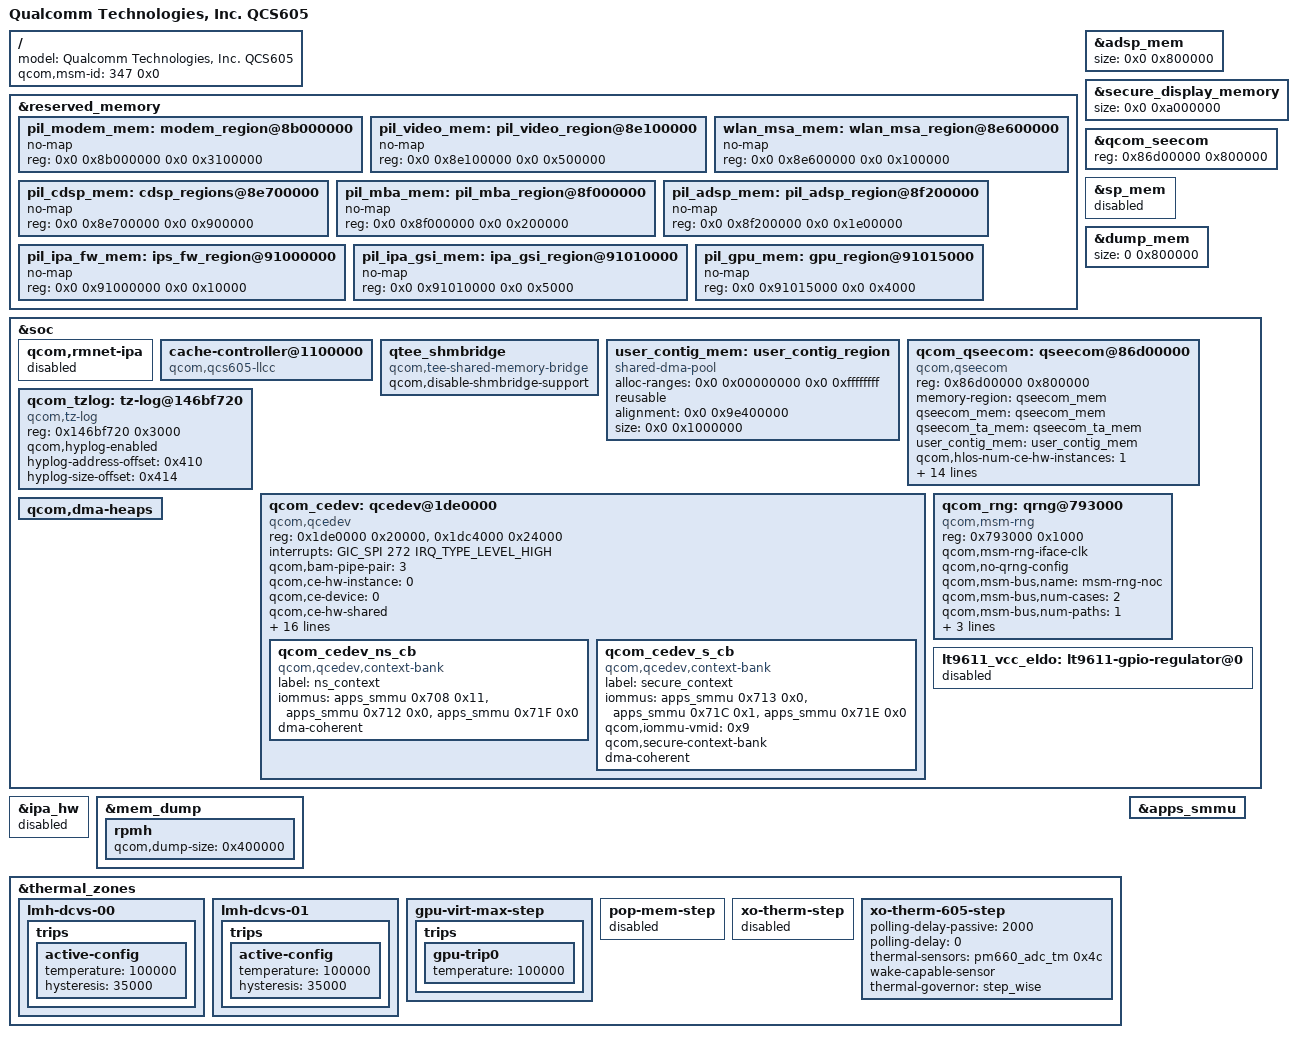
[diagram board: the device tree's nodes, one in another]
#include "sda670.dtsi"

/ {
	model = "Qualcomm Technologies, Inc. QCS605";
	qcom,msm-id = <347 0x0>;
};

&reserved_memory {
	/delete-node/ modem_region@8b000000;
	/delete-node/ pil_video_region@92e00000;
	/delete-node/ wlan_msa_region@93300000;
	/delete-node/ cdsp_regions@93400000;
	/delete-node/ pil_mba_region@0x93c00000;
	/delete-node/ pil_adsp_region@93e00000;
	/delete-node/ ips_fw_region@0x95c00000;
	/delete-node/ ipa_gsi_region@0x95c10000;
	/delete-node/ gpu_region@0x95c15000;

	pil_modem_mem: modem_region@8b000000 {
		no-map;
		reg = <0x0 0x8b000000 0x0 0x3100000>;
	};

	pil_video_mem: pil_video_region@8e100000 {
		no-map;
		reg = <0x0 0x8e100000 0x0 0x500000>;
	};

	wlan_msa_mem: wlan_msa_region@8e600000 {
		no-map;
		reg = <0x0 0x8e600000 0x0 0x100000>;
	};

	pil_cdsp_mem: cdsp_regions@8e700000 {
		no-map;
		reg = <0x0 0x8e700000 0x0 0x900000>;
	};

	pil_mba_mem: pil_mba_region@8f000000 {
		no-map;
		reg = <0x0 0x8f000000 0x0 0x200000>;
	};

	pil_adsp_mem: pil_adsp_region@8f200000 {
		no-map;
		reg = <0x0 0x8f200000 0x0 0x1e00000>;
	};

	pil_ipa_fw_mem: ips_fw_region@91000000 {
		no-map;
		reg = <0x0 0x91000000 0x0 0x10000>;
	};

	pil_ipa_gsi_mem: ipa_gsi_region@91010000 {
		no-map;
		reg = <0x0 0x91010000 0x0 0x5000>;
	};

	pil_gpu_mem: gpu_region@91015000 {
		no-map;
		reg = <0x0 0x91015000 0x0 0x4000>;
	};
};

&adsp_mem {
	size = <0x0 0x800000>;
};

&secure_display_memory {
	size = <0x0 0xa000000>;
};

&qcom_seecom {
	reg = <0x86d00000 0x800000>;
	/delete-property/ qcom,appsbl-qseecom-support;
};

&sp_mem {
	status = "disabled";
};

&dump_mem {
	size = <0 0x800000>;
};

&soc {
	qcom,rmnet-ipa {
		status = "disabled";
	};

	cache-controller@1100000 {
		/delete-property/ compatible;
		compatible = "qcom,qcs605-llcc";
	};

	qtee_shmbridge {
		compatible = "qcom,tee-shared-memory-bridge";
		qcom,disable-shmbridge-support;
	};

	user_contig_mem: user_contig_region {
		compatible = "shared-dma-pool";
		alloc-ranges = <0x0 0x00000000 0x0 0xffffffff>;
		reusable;
		alignment = <0x0 0x9e400000>;
		size = <0x0 0x1000000>;
	};

	qcom_qseecom: qseecom@86d00000 {
		compatible = "qcom,qseecom";
		reg = <0x86d00000 0x800000>;
		reg-names = "secapp-region";
		memory-region = <&qseecom_mem>;
		qseecom_mem = <&qseecom_mem>;
		qseecom_ta_mem = <&qseecom_ta_mem>;
		user_contig_mem = <&user_contig_mem>;
		qcom,hlos-num-ce-hw-instances = <1>;
		qcom,hlos-ce-hw-instance = <0>;
		qcom,qsee-ce-hw-instance = <0>;
		qcom,disk-encrypt-pipe-pair = <2>;
		qcom,no-clock-support;
		qcom,appsbl-qseecom-support;
		qcom,msm-bus,name = "qseecom-noc";
		qcom,msm-bus,num-cases = <4>;
		qcom,msm-bus,num-paths = <1>;
		qcom,msm-bus,vectors-KBps =
				<125 512 0 0>,
				<125 512 200000 400000>,
				<125 512 300000 800000>,
				<125 512 400000 1000000>;
		qcom,ce-opp-freq = <171430000>;
		qcom,qsee-reentrancy-support = <2>;
	};

	qcom_tzlog: tz-log@146bf720 {
		compatible = "qcom,tz-log";
		reg = <0x146bf720 0x3000>;
		qcom,hyplog-enabled;
		hyplog-address-offset = <0x410>;
		hyplog-size-offset = <0x414>;
	};

	qcom_cedev: qcedev@1de0000 {
	compatible = "qcom,qcedev";
	reg = <0x1de0000 0x20000>,
		<0x1dc4000 0x24000>;
	reg-names = "crypto-base","crypto-bam-base";
	interrupts = <GIC_SPI 272 IRQ_TYPE_LEVEL_HIGH>;
	qcom,bam-pipe-pair = <3>;
	qcom,ce-hw-instance = <0>;
	qcom,ce-device = <0>;
	qcom,ce-hw-shared;
	qcom,bam-ee = <0>;
	qcom,msm-bus,name = "qcedev-noc";
	qcom,msm-bus,num-cases = <2>;
	qcom,msm-bus,num-paths = <1>;
	qcom,msm-bus,vectors-KBps =
		<125 512 0 0>,
		<125 512 393600 393600>;
	clock-names = "core_clk_src", "core_clk",
		"iface_clk", "bus_clk";
	clocks = <&gcc GCC_CE1_CLK>,
		<&gcc GCC_CE1_CLK>,
		<&gcc GCC_CE1_AHB_CLK>,
		<&gcc GCC_CE1_AXI_CLK>;
	qcom,ce-opp-freq = <171430000>;
	qcom,request-bw-before-clk;
	qcom,smmu-s1-enable;
	interconnect-names = "data_path";
	interconnects = <&aggre2_noc MASTER_CRYPTO &mc_virt SLAVE_EBI1>;
	iommus = <&apps_smmu 0x706 0x1>,
		<&apps_smmu 0x716 0x1>;
	qcom,iommu-dma = "atomic";

	qcom_cedev_ns_cb {
		compatible = "qcom,qcedev,context-bank";
		label = "ns_context";
		iommus = <&apps_smmu 0x708 0x11>,
			<&apps_smmu 0x712 0x0>,
			<&apps_smmu 0x71F 0x0>;
		dma-coherent;
	};

	qcom_cedev_s_cb {
		compatible = "qcom,qcedev,context-bank";
		label = "secure_context";
		iommus = <&apps_smmu 0x713 0x0>,
			<&apps_smmu 0x71C 0x1>,
			<&apps_smmu 0x71E 0x0>;
		qcom,iommu-vmid = <0x9>;
		qcom,secure-context-bank;
		dma-coherent;
	};
};

	qcom_rng: qrng@793000 {
		compatible = "qcom,msm-rng";
		reg = <0x793000 0x1000>;
		qcom,msm-rng-iface-clk;
		qcom,no-qrng-config;
		qcom,msm-bus,name = "msm-rng-noc";
		qcom,msm-bus,num-cases = <2>;
		qcom,msm-bus,num-paths = <1>;
		qcom,msm-bus,vectors-KBps =
			<1 618 0 0>,    /* No vote */
			<1 618 0 800>;  /* 100 KHz */
		clocks = <&gcc GCC_PRNG_AHB_CLK>;
		clock-names = "km_clk_src";
	};

	lt9611_vcc_eldo: lt9611-gpio-regulator@0 {
		status = "disabled";
	};

	qcom,dma-heaps {
		/delete-node/ qcom,sp_hlos;
	};
};

&ipa_hw {
	status = "disabled";
};

&mem_dump {
	rpmh {
		qcom,dump-size = <0x400000>;
	};
};

&thermal_zones {
	lmh-dcvs-00 {
		trips {
			active-config {
				temperature = <100000>;
				hysteresis = <35000>;
			};
		};
	};

	lmh-dcvs-01 {
		trips {
			active-config {
				temperature = <100000>;
				hysteresis = <35000>;
			};
		};
	};

	gpu-virt-max-step {
		trips {
			gpu-trip0 {
				temperature = <100000>;
			};
		};
	};

	pop-mem-step {
		status = "disabled";
	};

	xo-therm-step {
		status = "disabled";
	};

	xo-therm-605-step {
		polling-delay-passive = <2000>;
		polling-delay = <0>;
		thermal-sensors = <&pm660_adc_tm 0x4c>;
		wake-capable-sensor;
		thermal-governor = "step_wise";
		status = "ok";
	};
};

&apps_smmu {
	/delete-property/ qcom,actlr;
};
